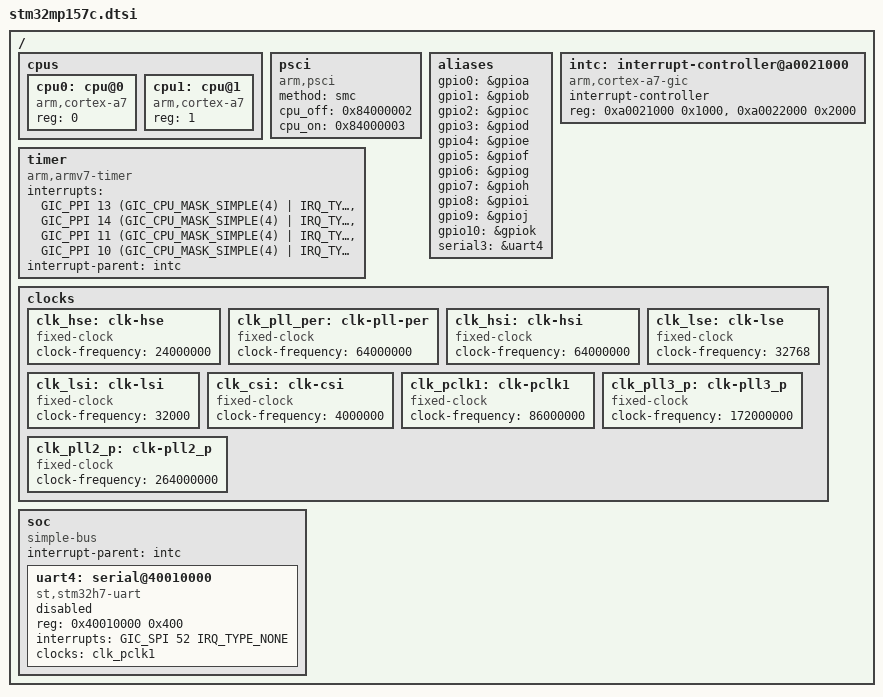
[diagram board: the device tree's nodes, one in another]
/* SPDX-License-Identifier: (GPL-2.0+ OR BSD-3-Clause) */
/*
 * Copyright (C) STMicroelectronics 2017 - All Rights Reserved
 * Author: Ludovic Barre <ludovic.barre@st.com> for STMicroelectronics.
 */
#include <dt-bindings/interrupt-controller/arm-gic.h>

/ {
	#address-cells = <1>;
	#size-cells = <1>;

	cpus {
		#address-cells = <1>;
		#size-cells = <0>;

		cpu0: cpu@0 {
			compatible = "arm,cortex-a7";
			device_type = "cpu";
			reg = <0>;
		};

		cpu1: cpu@1 {
			compatible = "arm,cortex-a7";
			device_type = "cpu";
			reg = <1>;
		};
	};

	psci {
		compatible = "arm,psci";
		method = "smc";
		cpu_off = <0x84000002>;
		cpu_on = <0x84000003>;
	};

	aliases {
		gpio0 = &gpioa;
		gpio1 = &gpiob;
		gpio2 = &gpioc;
		gpio3 = &gpiod;
		gpio4 = &gpioe;
		gpio5 = &gpiof;
		gpio6 = &gpiog;
		gpio7 = &gpioh;
		gpio8 = &gpioi;
		gpio9 = &gpioj;
		gpio10 = &gpiok;
		serial3 = &uart4;
	};

	intc: interrupt-controller@a0021000 {
		compatible = "arm,cortex-a7-gic";
		#interrupt-cells = <3>;
		interrupt-controller;
		reg = <0xa0021000 0x1000>,
		      <0xa0022000 0x2000>;
	};

	timer {
		compatible = "arm,armv7-timer";
		interrupts = <GIC_PPI 13 (GIC_CPU_MASK_SIMPLE(4) | IRQ_TYPE_LEVEL_LOW)>,
			     <GIC_PPI 14 (GIC_CPU_MASK_SIMPLE(4) | IRQ_TYPE_LEVEL_LOW)>,
			     <GIC_PPI 11 (GIC_CPU_MASK_SIMPLE(4) | IRQ_TYPE_LEVEL_LOW)>,
			     <GIC_PPI 10 (GIC_CPU_MASK_SIMPLE(4) | IRQ_TYPE_LEVEL_LOW)>;
		interrupt-parent = <&intc>;
	};

	clocks {
		clk_hse: clk-hse {
			#clock-cells = <0>;
			compatible = "fixed-clock";
			clock-frequency = <24000000>;
		};

		clk_pll_per: clk-pll-per {
			#clock-cells = <0>;
			compatible = "fixed-clock";
			clock-frequency = <64000000>;
		};

		clk_hsi: clk-hsi {
			#clock-cells = <0>;
			compatible = "fixed-clock";
			clock-frequency = <64000000>;
		};

		clk_lse: clk-lse {
			#clock-cells = <0>;
			compatible = "fixed-clock";
			clock-frequency = <32768>;
		};

		clk_lsi: clk-lsi {
			#clock-cells = <0>;
			compatible = "fixed-clock";
			clock-frequency = <32000>;
		};

		clk_csi: clk-csi {
			#clock-cells = <0>;
			compatible = "fixed-clock";
			clock-frequency = <4000000>;
		};

		clk_pclk1: clk-pclk1 {
			#clock-cells = <0>;
			compatible = "fixed-clock";
			clock-frequency = <86000000>;
		};

		clk_pll3_p: clk-pll3_p {
			#clock-cells = <0>;
			compatible = "fixed-clock";
			clock-frequency = <172000000>;
		};

		clk_pll2_p: clk-pll2_p {
			#clock-cells = <0>;
			compatible = "fixed-clock";
			clock-frequency = <264000000>;
		};
	};

	soc {
		compatible = "simple-bus";
		#address-cells = <1>;
		#size-cells = <1>;
		interrupt-parent = <&intc>;
		ranges;

		uart4: serial@40010000 {
			compatible = "st,stm32h7-uart";
			reg = <0x40010000 0x400>;
			interrupts = <GIC_SPI 52 IRQ_TYPE_NONE>;
			clocks = <&clk_pclk1>;
			status = "disabled";
		};
	};
};
